# STM32G051 register map
File version: 1.4
CPU: CM0 r0p1, little endian, MPU, no FPU, 2 interrupt priority bits
Registers are 32-bit, read-write, reset 0x0 unless marked. A register's access mark holds for its fields unless they carry their own. Offsets are from the block's base; [hi:lo] are bit positions; 'fields as' and 'values as' point back to an identical list.

## FLASH
Base 0x40022000
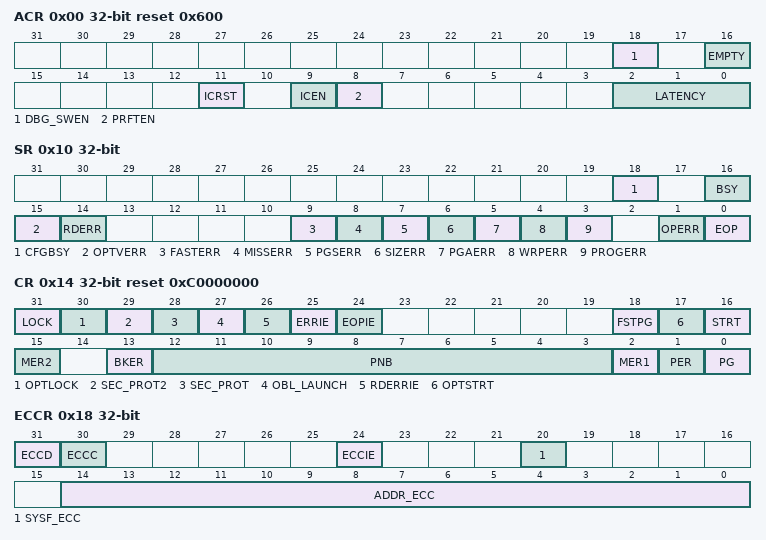
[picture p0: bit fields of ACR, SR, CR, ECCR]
0x00 ACR reset 0x600 — Access control register
  [18] DBG_SWEN — Debug access software enable
  [16] EMPTY — Flash User area empty
  [11] ICRST — Instruction cache reset
  [9] ICEN — Instruction cache enable
  [8] PRFTEN — Prefetch enable
  [2:0] LATENCY
0x08 KEYR wo — Flash key register
  [31:0] KEY — KEYR
0x0C OPTKEYR wo — Option byte key register
  [31:0] OPTKEY — Option byte key
0x10 SR — Status register
  [18] CFGBSY — Programming or erase configuration busy.
  [16] BSY — Busy
  [15] OPTVERR — Option and Engineering bits loading validity error
  [14] RDERR — PCROP read error
  [9] FASTERR — Fast programming error
  [8] MISSERR — Fast programming data miss error
  [7] PGSERR — Programming sequence error
  [6] SIZERR — Size error
  [5] PGAERR — Programming alignment error
  [4] WRPERR — Write protected error
  [3] PROGERR — Programming error
  [1] OPERR — Operation error
  [0] EOP — End of operation
0x14 CR reset 0xC0000000 — Flash control register
  [31] LOCK — FLASH_CR Lock
  [30] OPTLOCK — Options Lock
  [29] SEC_PROT2 — Securable memory area protection enable, Bank 2
  [28] SEC_PROT — Securable memory area protection enable
  [27] OBL_LAUNCH — Force the option byte loading
  [26] RDERRIE — PCROP read error interrupt enable
  [25] ERRIE — Error interrupt enable
  [24] EOPIE — End of operation interrupt enable
  [18] FSTPG — Fast programming
  [17] OPTSTRT — Options modification start
  [16] STRT — Start
  [15] MER2 — Mass erase, Bank 2
  [13] BKER — Bank selection for erase operation
  [12:3] PNB — Page number
  [2] MER1 — Mass erase
  [1] PER — Page erase
  [0] PG — Programming
0x18 ECCR access per field — Flash ECC register
  [31] ECCD rw — ECC detection
  [30] ECCC rw — ECC correction
  [24] ECCIE rw — ECC correction interrupt enable
  [20] SYSF_ECC ro — ECC fail for Corrected ECC Error or Double ECC Error in info block
  [14:0] ADDR_ECC ro — ECC fail address
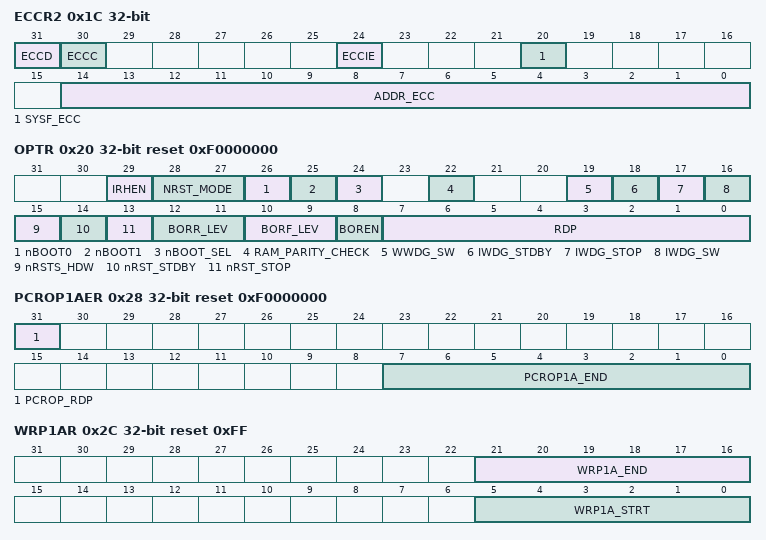
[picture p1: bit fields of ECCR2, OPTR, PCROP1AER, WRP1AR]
0x1C ECCR2 access per field — Flash ECC register 2
  fields as ECCR
0x20 OPTR reset 0xF0000000 — Flash option register
  [29] IRHEN — Internal reset holder enable bit
  [28:27] NRST_MODE
  [26] nBOOT0 — nBOOT0 option bit
  [25] nBOOT1 — Boot configuration
  [24] nBOOT_SEL
  [22] RAM_PARITY_CHECK — SRAM parity check control
  [19] WWDG_SW — Window watchdog selection
  [18] IWDG_STDBY — Independent watchdog counter freeze in Standby mode
  [17] IWDG_STOP — Independent watchdog counter freeze in Stop mode
  [16] IWDG_SW — Independent watchdog selection
  [15] nRSTS_HDW
  [14] nRST_STDBY
  [13] nRST_STOP
  [12:11] BORR_LEV — These bits contain the VDD supply level threshold that releases the reset.
  [10:9] BORF_LEV — These bits contain the VDD supply level threshold that activates the reset
  [8] BOREN — BOR reset Level
  [7:0] RDP — Read protection level
0x24 PCROP1ASR ro reset 0xF0000000 — Flash PCROP zone A Start address register
  [7:0] PCROP1A_STRT — PCROP1A area start offset
0x28 PCROP1AER ro reset 0xF0000000 — Flash PCROP zone A End address register
  [31] PCROP_RDP — PCROP area preserved when RDP level decreased
  [7:0] PCROP1A_END — PCROP1A area end offset
0x2C WRP1AR reset 0xFF — Flash WRP area A address register
  [21:16] WRP1A_END — WRP area A end offset
  [5:0] WRP1A_STRT — WRP area A start offset
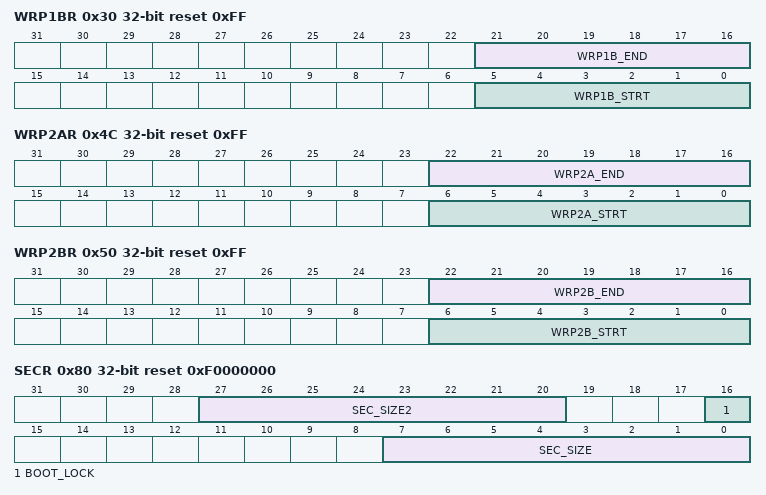
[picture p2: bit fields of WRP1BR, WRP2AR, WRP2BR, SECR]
0x30 WRP1BR reset 0xFF — Flash WRP area B address register
  [21:16] WRP1B_END — WRP area B end offset
  [5:0] WRP1B_STRT — WRP area B start offset
0x34 PCROP1BSR ro reset 0xF0000000 — Flash PCROP zone B Start address register
  [7:0] PCROP1B_STRT — PCROP1B area start offset
0x38 PCROP1BER reset 0xF0000000 — Flash PCROP area B End address register
  [8:0] PCROP1B_END — PCROP1B area end offset
0x44 PCROP2ASR — Flash PCROP2 area A start address register
  [8:0] PCROP2A_STRT — PCROP2A area start offset, bank2
0x48 PCROP2AER — Flash PCROP2 area A end address register
  [8:0] PCROP2A_END — PCROP2A area end offset, bank2
0x4C WRP2AR reset 0xFF — Flash WRP2 area A address register
  [22:16] WRP2A_END — WRP area A end offset, Bank 2
  [6:0] WRP2A_STRT — WRP area A start offset, Bank 2
0x50 WRP2BR reset 0xFF — Flash WRP2 area B address register
  [22:16] WRP2B_END — WRP area B end offset, Bank 2
  [6:0] WRP2B_STRT — WRP area B start offset, Bank 2
0x54 PCROP2BSR — FLASH PCROP2 area B start address register
  [8:0] PCROP2B_STRT — PCROP2B area start offset, Bank 2
0x58 PCROP2BER — FLASH PCROP2 area B end address register
  [8:0] PCROP2B_END — PCROP2B area end offset, Bank 2
0x80 SECR reset 0xF0000000 — Flash Security register
  [27:20] SEC_SIZE2 — Securable memory area size
  [16] BOOT_LOCK — used to force boot from user area
  [7:0] SEC_SIZE — Securable memory area size
